# GD32EPRTxxA register map
File version: 1.0
CPU: CM33 r0p4, little endian, MPU, FPU, 4 interrupt priority bits
Registers are 32-bit, read-write, reset 0x0 unless marked. A register's access mark holds for its fields unless they carry their own. Offsets are from the block's base; [hi:lo] are bit positions; {n}, {i} and the like mark numbered series.

## TIMER9 — General-purpose-timers
Base 0x40015000
Same registers: TIMER12 0x40001C00, TIMER13 0x40002000, TIMER10 0x40015400
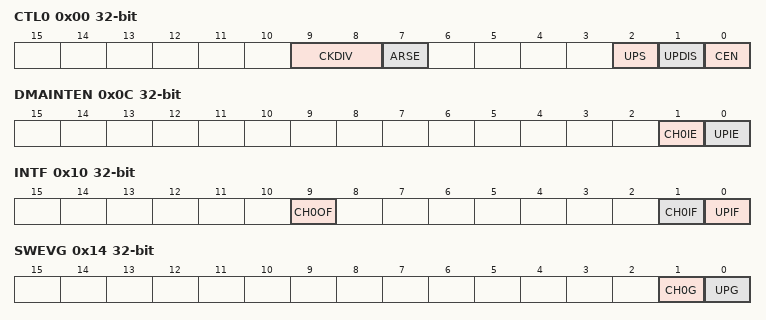
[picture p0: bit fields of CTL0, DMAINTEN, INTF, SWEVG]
0x00 CTL0 — control register 0
  [9:8] CKDIV — Clock division
  [7] ARSE — Auto-reload shadow enable
  [2] UPS — Update source
  [1] UPDIS — Update disable
  [0] CEN — Counter enable
0x04 CTL1 — control register 1
  [6:4] MMC — Master mode control
0x0C DMAINTEN — DMA/Interrupt enable register
  [1] CH0IE — Channel 0 capture/compare interrupt enable
  [0] UPIE — Update interrupt enable
0x10 INTF — interrupt flag register
  [9] CH0OF — Channel 0 over capture flag
  [1] CH0IF — Channel 0 capture/compare interrupt flag
  [0] UPIF — Update interrupt flag
0x14 SWEVG wo — event generation register
  [1] CH0G — Channel 0 capture or compare event generation
  [0] UPG — Update generation
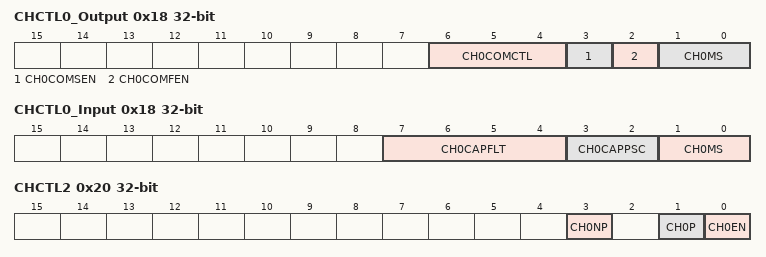
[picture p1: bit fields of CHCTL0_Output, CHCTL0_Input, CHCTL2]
0x18 CHCTL0_Output — Channel control register 0 (output mode)
  [6:4] CH0COMCTL — Channel 0 compare output control
  [3] CH0COMSEN — Channel 0 compare output shadow enable
  [2] CH0COMFEN — Channel 0 output compare fast enable
  [1:0] CH0MS — Channel 0 I/O mode selection
0x18 CHCTL0_Input (alternate view of CHCTL0_Output) — Channel control register 0 ( (input mode)
  [7:4] CH0CAPFLT — Channel 0 input capture filter control
  [3:2] CH0CAPPSC — Channel 0 input capture prescaler
  [1:0] CH0MS — Channel 0 mode selection
0x20 CHCTL2 — Channel control register 2
  [3] CH0NP — Channel 0 complementary output polarity
  [1] CH0P — Channel 0 capture/compare polarity
  [0] CH0EN — Channel 0 capture/compare function enable
0x24 CNT — Counter register
  [15:0] CNT — current counter value
0x28 PSC — Prescaler register
  [15:0] PSC — Prescaler value of the counter clock
0x2C CAR — Counter auto reload register
  [15:0] CARL — Counter auto reload value
0x34 CH0CV — Channel 0 capture/compare value register
  [15:0] CH0VAL — Capture or compare value of channel 0
0xFC CFG — configuration register
  [1] CHVSEL — Write CHxVAL register selection

## TIMER15 — General level4 timer
Base 0x40014400
Same registers: TIMER16 0x40014800
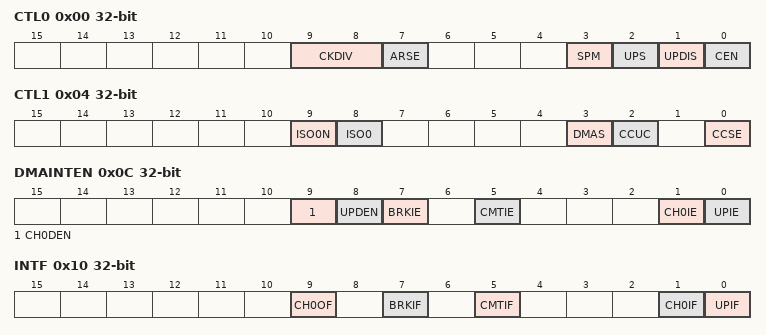
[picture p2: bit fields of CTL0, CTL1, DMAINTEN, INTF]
0x00 CTL0 — Control register 0
  [9:8] CKDIV — Clock division
  [7] ARSE — Auto-reload shadow enable
  [3] SPM — Single pulse mode.
  [2] UPS — Update source
  [1] UPDIS — Update disable.
  [0] CEN — Counter enable
0x04 CTL1 — Control register 1
  [9] ISO0N — Idle state of channel 0 complementary output
  [8] ISO0 — Idle state of channel 0 output
  [3] DMAS — DMA request source selection
  [2] CCUC — Commutation control shadow register update control
  [0] CCSE — Commutation control shadow enable
0x0C DMAINTEN — DMA and interrupt enable register
  [9] CH0DEN — Channel 0 capture/compare DMA request enable
  [8] UPDEN — Update DMA request enable
  [7] BRKIE — Break interrupt enable
  [5] CMTIE — Commutation interrupt enable
  [1] CH0IE — Channel 0 capture/compare interrupt enable
  [0] UPIE — Update interrupt enable
0x10 INTF — Interrupt flag register
  [9] CH0OF — Channel 0 over capture flag
  [7] BRKIF — Break interrupt flag
  [5] CMTIF — Channel commutation interrupt flag
  [1] CH0IF — Channel 0 s capture/compare interrupt flag
  [0] UPIF — Update interrupt flag
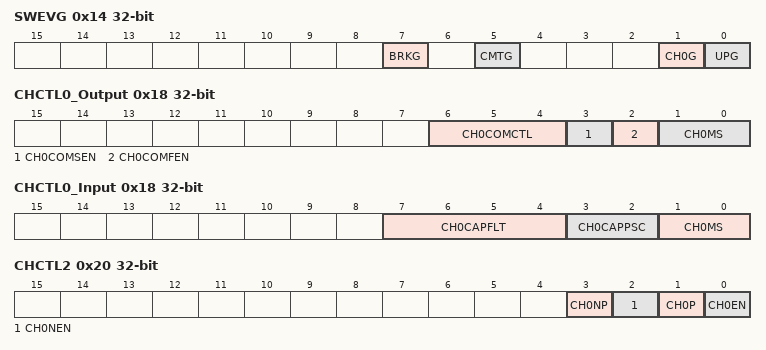
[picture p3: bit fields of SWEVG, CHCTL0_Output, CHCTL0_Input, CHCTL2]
0x14 SWEVG wo — Software event generation register
  [7] BRKG — Break event generation
  [5] CMTG — Channel commutation event generation
  [1] CH0G — Channel 0 s capture or compare event generation
  [0] UPG — Update event generation
0x18 CHCTL0_Output — Channel control register 0 (output mode)
  [6:4] CH0COMCTL — Channel 0 compare output control
  [3] CH0COMSEN — Channel 0 compare output shadow enable
  [2] CH0COMFEN — Channel 0 output compare fast enable
  [1:0] CH0MS — Channel 0 I/O mode selection
0x18 CHCTL0_Input (alternate view of CHCTL0_Output) — Channel control register 0 ( (input mode)
  [7:4] CH0CAPFLT — Channel 0 input capture filter control
  [3:2] CH0CAPPSC — Channel 0 input capture prescaler
  [1:0] CH0MS — Channel 0 mode selection
0x20 CHCTL2 — Channel control register 2
  [3] CH0NP — Channel 0 complementary output polarity
  [2] CH0NEN — Channel 0 complementary output enable
  [1] CH0P — Channel 0 capture/compare function polarity
  [0] CH0EN — Channel 0 capture/compare function enable
0x24 CNT — Counter register
  [15:0] CNT — This bit-filed indicates the current counter value. Writing to this bit-filed can change the value of the counter.
0x28 PSC — Prescaler register
  [15:0] PSC — Prescaler value of the counter clock
0x2C CAR — Counter auto reload register
  [15:0] CARL — Counter auto reload value
0x30 CREP — Counter repetition register
  [7:0] CREP — Counter repetition value
0x34 CH0CV — Channel 0 capture/compare value register
  [15:0] CH0VAL — Capture or compare value of channel0
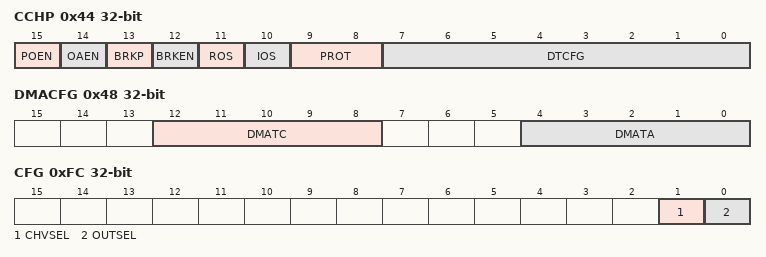
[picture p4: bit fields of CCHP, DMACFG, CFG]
0x44 CCHP — Complementary channel protection register
  [15] POEN — Primary output enable
  [14] OAEN — Output automatic enable
  [13] BRKP — Break polarity
  [12] BRKEN — Break enable
  [11] ROS — Run mode off-state enable
  [10] IOS — Idle mode off-state enable
  [9:8] PROT — Complementary register protect control
  [7:0] DTCFG — Dead time configure
0x48 DMACFG — DMA configuration register
  [12:8] DMATC — DMA transfer count
  [4:0] DMATA — DMA transfer access start address
0x4C DMATB — DMA transfer buffer register
  [15:0] DMATB — DMA transfer buffer
0xFC CFG — Configuration register
  [1] CHVSEL — Write CHxVAL register selection
  [0] OUTSEL — The output value selection

## WWDGT — Window watchdog timer
Base 0x40002C00
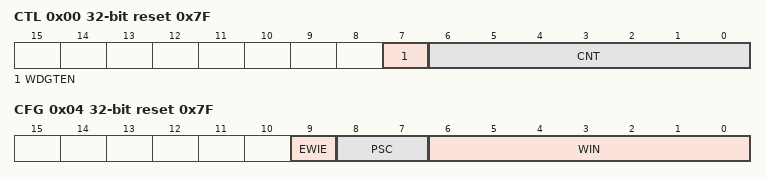
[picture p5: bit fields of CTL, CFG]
0x00 CTL reset 0x7F — Control register
  [7] WDGTEN — Activation bit
  [6:0] CNT — 7-bit counter
0x04 CFG reset 0x7F — Configuration register
  [9] EWIE — Early wakeup interrupt
  [8:7] PSC — Prescaler
  [6:0] WIN — 7-bit window value
0x08 STAT — Status register
  [0] EWIF — Early wakeup interrupt flag

## USBD — Universal serial bus full-speed device interface
Base 0x40005C00
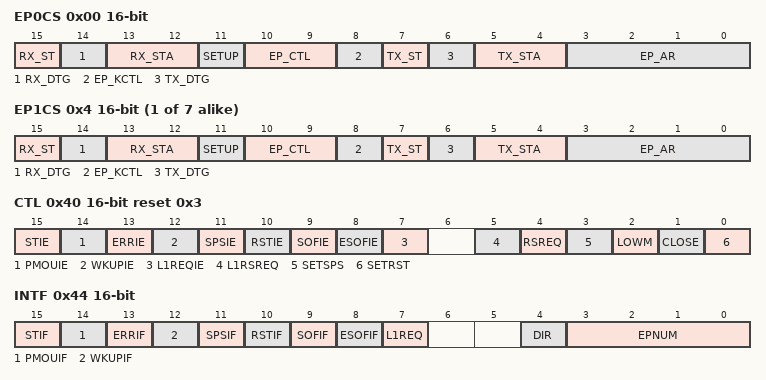
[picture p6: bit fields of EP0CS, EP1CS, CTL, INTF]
0x00 EP0CS 16-bit — endpoint 0 register
  [15] RX_ST — Correct transfer for reception
  [14] RX_DTG — Data Toggle, for reception transfers
  [13:12] RX_STA — Status bits, for reception transfers
  [11] SETUP — Setup transaction completed
  [10:9] EP_CTL — Endpoint type
  [8] EP_KCTL — Endpoint kind
  [7] TX_ST — Correct Transfer for transmission
  [6] TX_DTG — Data PID Toggle, for transmission transfers
  [5:4] TX_STA — Status bits, for transmission transfers
  [3:0] EP_AR — Endpoint address
{0x0+4i} EP{i}CS 16-bit (i=1..7) — endpoint {i} register
  [15] RX_ST — Correct transfer for reception
  [14] RX_DTG — Data Toggle, for reception transfers
  [13:12] RX_STA — Status bits, for reception transfers
  [11] SETUP — Setup transaction completed
  [10:9] EP_CTL — Endpoint type
  [8] EP_KCTL — Endpoint kind
  [7] TX_ST — Correct Transfer for transmission
  [6] TX_DTG — Data Toggle, for transmission transfers
  [5:4] TX_STA — Status bits, for transmission transfers
  [3:0] EP_AR — Endpoint address
0x40 CTL 16-bit reset 0x3 — control register
  [15] STIE — Successful transfer interrupt enable
  [14] PMOUIE — Packet memory area over / underrun interrupt enable
  [13] ERRIE — Error interrupt mask
  [12] WKUPIE — Wakeup interrupt enable
  [11] SPSIE — Suspend mode interrupt mask
  [10] RSTIE — USB reset interrupt mask
  [9] SOFIE — Start of frame interrupt mask
  [8] ESOFIE — Expected start of frame interrupt enable
  [7] L1REQIE — LPM L1 state request interrupt enable
  [5] L1RSREQ — LPM L1 resume request
  [4] RSREQ — Resume request
  [3] SETSPS — Set suspend
  [2] LOWM — Low-power mode
  [1] CLOSE — Close state
  [0] SETRST — Set reset
0x44 INTF 16-bit — interrupt flag register
  [15] STIF — Successful transfer interrupt flag
  [14] PMOUIF — Packet memory area over / underrun interrupt flag
  [13] ERRIF — Error interrupt flag
  [12] WKUPIF — Wakeup interrupt flag
  [11] SPSIF — Suspend mode interrupt flag
  [10] RSTIF — reset interrupt flag
  [9] SOFIF — start of frame interrupt flag
  [8] ESOFIF — Expected start of frame interrupt flag
  [7] L1REQ — LPM L1 transaction is successful
  [4] DIR — Direction of transaction
  [3:0] EPNUM — Endpoint Identifier
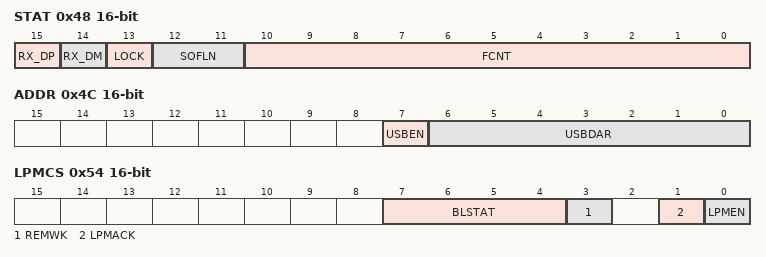
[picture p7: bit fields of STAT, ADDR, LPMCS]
0x48 STAT 16-bit ro — Status register
  [15] RX_DP — Receive data + line status
  [14] RX_DM — Receive data - line status
  [13] LOCK — Locked the USB
  [12:11] SOFLN — Lost SOF number
  [10:0] FCNT — Frame number counter
0x4C ADDR 16-bit — device address register
  [7] USBEN — USB device enable
  [6:0] USBDAR — Device address
0x50 BADDR 16-bit — Buffer address register
  [15:3] BAR — Buffer address
0x54 LPMCS 16-bit — USB LPM control and status register
  [7:4] BLSTAT — bLinkState value
  [3] REMWK — bRemoteWake value
  [1] LPMACK — LPM token acknowledge enable
  [0] LPMEN — LPM support enable
